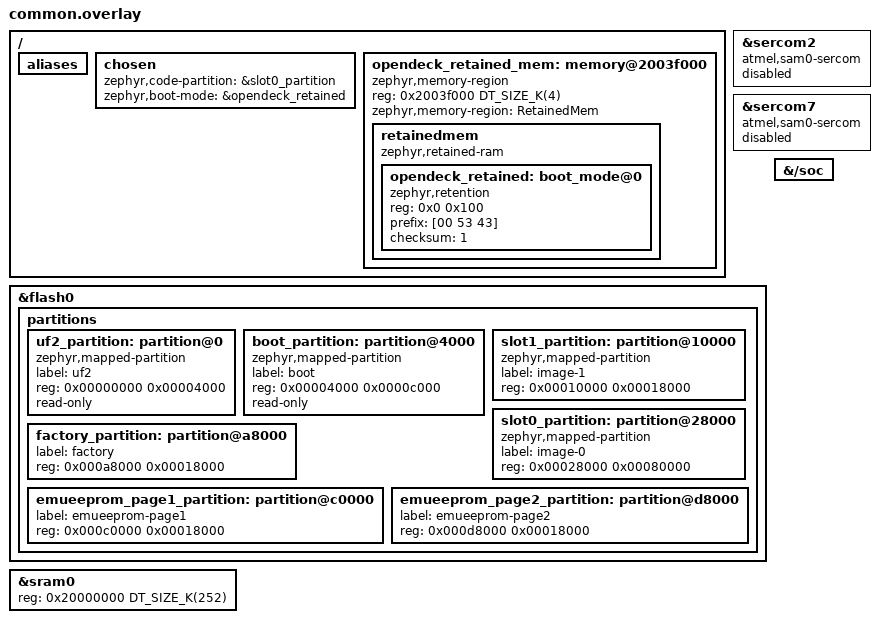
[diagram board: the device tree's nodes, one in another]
/ {
    aliases {
        /delete-property/ sdhc0;
    };
};

&sercom2 {
    compatible = "atmel,sam0-sercom";
    status = "disabled";
    /delete-property/ dipo;
    /delete-property/ dopo;
    /delete-property/ cs-gpios;
    /delete-property/ pinctrl-0;
    /delete-property/ pinctrl-names;
    /delete-property/ #address-cells;
    /delete-property/ #size-cells;

    /delete-node/ sdhc@0;
};

&sercom7 {
    compatible = "atmel,sam0-sercom";
    status = "disabled";
    /delete-property/ dipo;
    /delete-property/ dopo;
    /delete-property/ pinctrl-0;
    /delete-property/ pinctrl-names;
};

&flash0 {
    /delete-node/ partitions;

    partitions {
        #address-cells = <1>;
        #size-cells = <1>;

        uf2_partition: partition@0 {
            compatible = "zephyr,mapped-partition";
            label = "uf2";
            reg = <0x00000000 0x00004000>;
            read-only;
        };

        boot_partition: partition@4000 {
            compatible = "zephyr,mapped-partition";
            label = "boot";
            reg = <0x00004000 0x0000c000>;
            read-only;
        };

        /* image-1 is the OpenDeck bootloader; keep it before image-0 so merged UF2 files stay compact. */
        slot1_partition: partition@10000 {
            compatible = "zephyr,mapped-partition";
            label = "image-1";
            reg = <0x00010000 0x00018000>;
        };

        slot0_partition: partition@28000 {
            compatible = "zephyr,mapped-partition";
            label = "image-0";
            reg = <0x00028000 0x00080000>;
        };

        factory_partition: partition@a8000 {
            label = "factory";
            reg = <0x000a8000 0x00018000>;
        };

        emueeprom_page1_partition: partition@c0000 {
            label = "emueeprom-page1";
            reg = <0x000c0000 0x00018000>;
        };

        emueeprom_page2_partition: partition@d8000 {
            label = "emueeprom-page2";
            reg = <0x000d8000 0x00018000>;
        };
    };
};

&{/soc} {
    /delete-node/ pinmux@41008000;
};

&sram0 {
    reg = <0x20000000 DT_SIZE_K(252)>;
};

/ {
    chosen {
        zephyr,code-partition = &slot0_partition;
        zephyr,boot-mode = &opendeck_retained;
    };

    opendeck_retained_mem: memory@2003f000 {
        compatible = "zephyr,memory-region", "mmio-sram";
        reg = <0x2003f000 DT_SIZE_K(4)>;
        zephyr,memory-region = "RetainedMem";
        status = "okay";

        retainedmem {
            compatible = "zephyr,retained-ram";
            status = "okay";
            #address-cells = <1>;
            #size-cells = <1>;

            opendeck_retained: boot_mode@0 {
                compatible = "zephyr,retention";
                status = "okay";
                reg = <0x0 0x100>;
                prefix = [00 53 43];
                checksum = <1>;
            };
        };
    };
};
